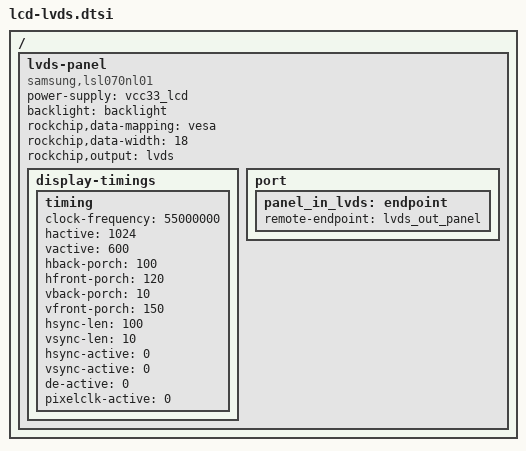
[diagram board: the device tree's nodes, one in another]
/ {

        lvds-panel {
                compatible = "samsung,lsl070nl01","simple-panel";
                power-supply = <&vcc33_lcd>;
                backlight = <&backlight>;
                
		rockchip,data-mapping = "vesa";
                rockchip,data-width = <18>;
                rockchip,output = "lvds";
                status = "okay";

                display-timings {
                        timing {
                                clock-frequency = <55000000>;
                                hactive = <1024>;
                                vactive = <600>;
                                hback-porch = <100>;
                                hfront-porch = <120>;
                                vback-porch = <10>;
                                vfront-porch = <150>;
                                hsync-len = <100>;
                                vsync-len = <10>;
                                hsync-active = <0>;
                                vsync-active = <0>;
                                de-active = <0>;
                                pixelclk-active = <0>;
                        };
                };

                port {
                        panel_in_lvds: endpoint {
                                remote-endpoint = <&lvds_out_panel>;
                        };
                };
        };
          
};

